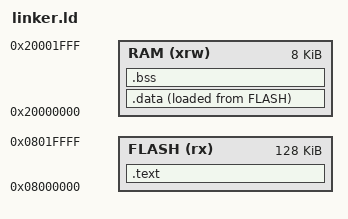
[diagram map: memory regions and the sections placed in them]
ENTRY(Reset_Handler)

MEMORY
{
    FLASH (rx)      : ORIGIN = 0x08000000, LENGTH = 128K
    RAM (xrw)       : ORIGIN = 0x20000000, LENGTH = 8K
}

SECTIONS
{
    .text :
    {
        KEEP(*(.isr_vector))
        *(.text*)
        *(.rodata*)
    } > FLASH

    .data :
    {
        _sdata = .;
        *(.data*)
        _edata = .;
    } > RAM AT > FLASH

    .bss :
    {
        _sbss = .;
        *(.bss*)
        _ebss = .;
    } > RAM

    _estack = ORIGIN(RAM) + LENGTH(RAM);
}
